AUTOSAR XML (schema 4-2-2)
package /UAES/ASW
  swc implementation Implementation: programming-language=C, sw-version=5.14.1, used-code-generator=Embedded Coder 7.5 (R2020b) 29-Jul-2020, vendor-id=0, behavior=InternalBehavior
    code-descriptors:
      code Code
        artifact-descriptors:
          short-label=PwrModMngt_ComCnvTx_c, category=SWSRC
          short-label=PwrModMngt_ComCnvTx_h, category=SWHDR
          short-label=rtwtypes_h, category=SWHDR
    resource consumption RsrcCons_PwrModMngt_ComCnvTx
package /UAES/ASW/SwComponentTypes
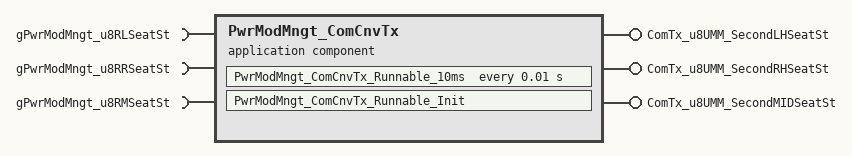
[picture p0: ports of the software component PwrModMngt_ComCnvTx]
  application sw component type PwrModMngt_ComCnvTx
    require port gPwrModMngt_u8RLSeatSt: nonqueued-receiver-com-spec{data-element=gPwrModMngt_u8RLSeatSt/Val, init-value=0}, required-interface=gPwrModMngt_u8RLSeatSt
    require port gPwrModMngt_u8RRSeatSt: nonqueued-receiver-com-spec{data-element=gPwrModMngt_u8RRSeatSt/Val, init-value=0}, required-interface=gPwrModMngt_u8RRSeatSt
    require port gPwrModMngt_u8RMSeatSt: nonqueued-receiver-com-spec{data-element=gPwrModMngt_u8RMSeatSt/Val, init-value=0}, required-interface=gPwrModMngt_u8RMSeatSt
    provide port ComTx_u8UMM_SecondLHSeatSt: nonqueued-sender-com-spec{data-element=ComTx_u8UMM_SecondLHSeatSt/Val, init-value=0}, provided-interface=ComTx_u8UMM_SecondLHSeatSt
    provide port ComTx_u8UMM_SecondRHSeatSt: nonqueued-sender-com-spec{data-element=ComTx_u8UMM_SecondRHSeatSt/Val, init-value=0}, provided-interface=ComTx_u8UMM_SecondRHSeatSt
    provide port ComTx_u8UMM_SecondMIDSeatSt: nonqueued-sender-com-spec{data-element=ComTx_u8UMM_SecondMIDSeatSt/Val, init-value=0}, provided-interface=ComTx_u8UMM_SecondMIDSeatSt
    behavior InternalBehavior: handle-termination-and-restart=NO-SUPPORT
      init event PwrModMngt_ComCnvTx_InitEvent: start-on-event=PwrModMngt_ComCnvTx_Runnable_Init
      timing event TMT_PwrModMngt_ComCnvTx_Runnable_10ms: start-on-event=PwrModMngt_ComCnvTx_Runnable_10ms, period=0.01
      runnable PwrModMngt_ComCnvTx_Runnable_Init
      runnable PwrModMngt_ComCnvTx_Runnable_10ms
        data-receive-point-by-arguments:
          access IN_gPwrModMngt_u8RLSeatSt_Val: accessed-variable=gPwrModMngt_u8RLSeatSt.Val
          access IN_gPwrModMngt_u8RMSeatSt_Val: accessed-variable=gPwrModMngt_u8RMSeatSt.Val
          access IN_gPwrModMngt_u8RRSeatSt_Val: accessed-variable=gPwrModMngt_u8RRSeatSt.Val
        data-send-points:
          access OUT_ComTx_u8UMM_SecondLHSeatSt_Val: accessed-variable=ComTx_u8UMM_SecondLHSeatSt.Val
          access OUT_ComTx_u8UMM_SecondRHSeatSt_Val: accessed-variable=ComTx_u8UMM_SecondRHSeatSt.Val
          access OUT_ComTx_u8UMM_SecondMIDSeatSt_Val: accessed-variable=ComTx_u8UMM_SecondMIDSeatSt.Val
package /UAES/ASW/PortInterfaces
  6 x sender receiver interface:
    gPwrModMngt_u8RLSeatSt
      data Val: category=VALUE, sw-calibration-access=READ-ONLY, type=uint8
    gPwrModMngt_u8RRSeatSt
      data Val: category=VALUE, sw-calibration-access=READ-ONLY, type=uint8
    gPwrModMngt_u8RMSeatSt
      data Val: category=VALUE, sw-calibration-access=READ-ONLY, type=uint8
    ComTx_u8UMM_SecondLHSeatSt
      data Val: category=VALUE, sw-calibration-access=READ-ONLY, type=uint8
    ComTx_u8UMM_SecondRHSeatSt
      data Val: category=VALUE, sw-calibration-access=READ-ONLY, type=uint8
    ComTx_u8UMM_SecondMIDSeatSt
      data Val: category=VALUE, sw-calibration-access=READ-ONLY, type=uint8
